# F28x7x_adc_regs register map
Vendor: Texas Instruments
Peripheral module from a debugger description file (folder C2000).
Address unit: 16 bits
Registers are 16-bit, read-write, no defined reset value unless marked. A register's access mark holds for its fields unless they carry their own. Offsets are as the file gives them; lines under a group give offsets from that group; [hi:lo] are bit positions; {n}, {i} and the like mark numbered series; 'fields as' and 'values as' point back to an identical list; <NAME> marks a mode.

## ADC_REGS
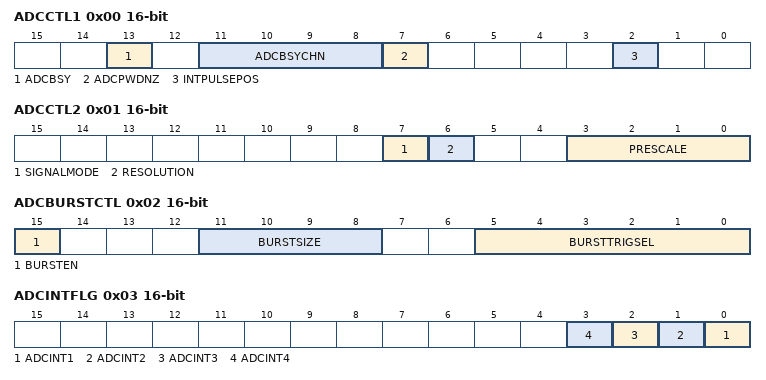
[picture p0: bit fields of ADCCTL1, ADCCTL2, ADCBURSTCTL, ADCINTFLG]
0x00 ADCCTL1 — ADC Control 1 Register
  [13] ADCBSY — ADC Busy
  [11:8] ADCBSYCHN — ADC Busy Channel
  [7] ADCPWDNZ — ADC Power Down
  [2] INTPULSEPOS — ADC Interrupt Pulse Position
0x01 ADCCTL2 — ADC Control 2 Register
  [7] SIGNALMODE — SOC Signaling Mode
  [6] RESOLUTION — SOC Conversion Resolution
  [3:0] PRESCALE — ADC Clock Prescaler
0x02 ADCBURSTCTL — ADC Burst Control Register
  [15] BURSTEN — SOC Burst Mode Enable
  [11:8] BURSTSIZE — SOC Burst Size Select
  [5:0] BURSTTRIGSEL — SOC Burst Trigger Source Select
0x03 ADCINTFLG — ADC Interrupt Flag Register
  [n-1] ADCINT{n} (n=1..4) — ADC Interrupt {n} Flag
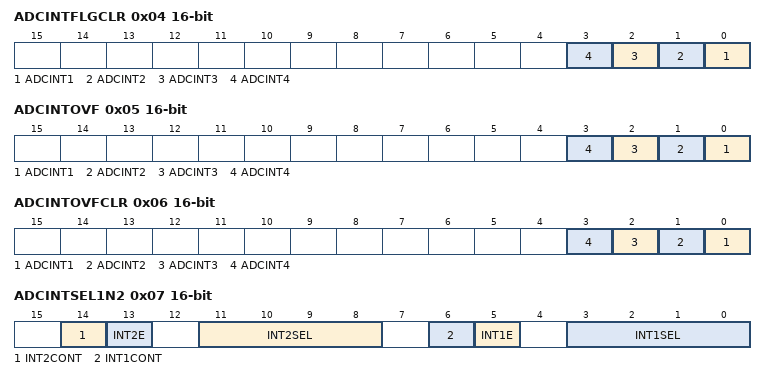
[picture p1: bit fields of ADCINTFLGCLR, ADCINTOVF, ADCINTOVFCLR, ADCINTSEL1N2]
0x04 ADCINTFLGCLR — ADC Interrupt Flag Clear Register
  [n-1] ADCINT{n} (n=1..4) — ADC Interrupt {n} Flag Clear
0x05 ADCINTOVF — ADC Interrupt Overflow Register
  [n-1] ADCINT{n} (n=1..4) — ADC Interrupt {n} Overflow Flags
0x06 ADCINTOVFCLR — ADC Interrupt Overflow Clear Register
  [n-1] ADCINT{n} (n=1..4) — ADC Interrupt {n} Overflow Clear Bits
0x07 ADCINTSEL1N2 — ADC Interrupt 1 and 2 Selection Register
  [14] INT2CONT — ADCINT2 Continuous Mode Enable
  [13] INT2E — ADCINT2 Interrupt Enable
  [11:8] INT2SEL — ADCINT2 EOC Source Select
  [6] INT1CONT — ADCINT1 Continuous Mode Enable
  [5] INT1E — ADCINT1 Interrupt Enable
  [3:0] INT1SEL — ADCINT1 EOC Source Select
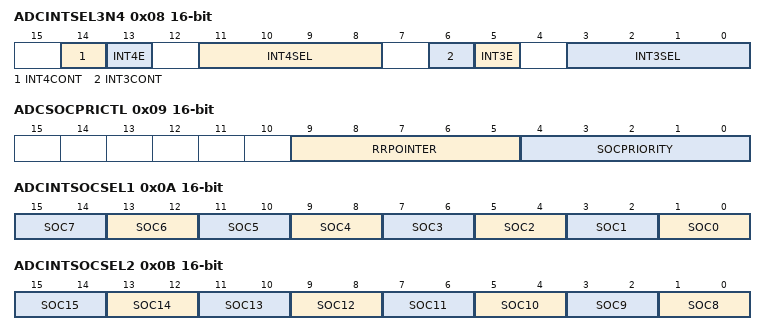
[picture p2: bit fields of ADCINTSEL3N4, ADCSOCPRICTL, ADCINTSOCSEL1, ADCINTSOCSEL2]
0x08 ADCINTSEL3N4 — ADC Interrupt 3 and 4 Selection Register
  [14] INT4CONT — ADCINT4 Continuous Mode Enable
  [13] INT4E — ADCINT4 Interrupt Enable
  [11:8] INT4SEL — ADCINT4 EOC Source Select
  [6] INT3CONT — ADCINT3 Continuous Mode Enable
  [5] INT3E — ADCINT3 Interrupt Enable
  [3:0] INT3SEL — ADCINT3 EOC Source Select
0x09 ADCSOCPRICTL — ADC SOC Priority Control Register
  [9:5] RRPOINTER — Round Robin Pointer
  [4:0] SOCPRIORITY
0x0A ADCINTSOCSEL1 — ADC Interrupt SOC Selection 1 Register
  [2n+1:2n] SOC{n} (n=0..7) — SOC{n} ADC Interrupt Trigger Select
0x0B ADCINTSOCSEL2 — ADC Interrupt SOC Selection 2 Register
  [2n-15:2n-16] SOC{n} (n=8..15) — SOC{n} ADC Interrupt Trigger Select
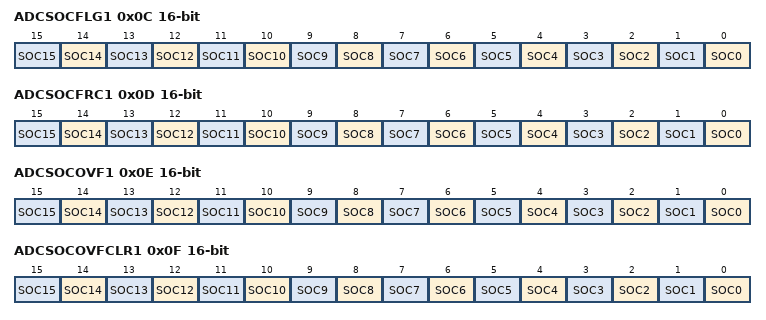
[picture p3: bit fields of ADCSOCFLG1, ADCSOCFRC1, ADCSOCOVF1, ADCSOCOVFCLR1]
0x0C ADCSOCFLG1 — ADC SOC Flag 1 Register
  [n] SOC{n} (n=0..15) — SOC{n} Start of Conversion Flag
0x0D ADCSOCFRC1 — ADC SOC Force 1 Register
  [n] SOC{n} (n=0..15) — SOC{n} Force Start of Conversion Bit
0x0E ADCSOCOVF1 — ADC SOC Overflow 1 Register
  [n] SOC{n} (n=0..15) — SOC{n} Start of Conversion Overflow Flag
0x0F ADCSOCOVFCLR1 — ADC SOC Overflow Clear 1 Register
  [n] SOC{n} (n=0..15) — SOC{n} Clear Start of Conversion Overflow Bit
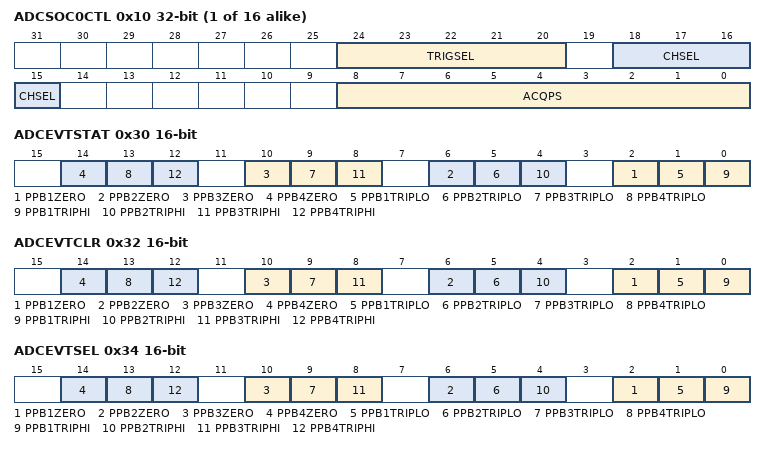
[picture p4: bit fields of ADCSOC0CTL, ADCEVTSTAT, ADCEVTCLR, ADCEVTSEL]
{0x10+2i} ADCSOC{i}CTL 32-bit (i=0..15) — ADC SOC{i} Control Register
  [24:20] TRIGSEL — SOC Trigger Source Select
  [18:15] CHSEL — SOC Channel Select
  [8:0] ACQPS — SOC Acquisition Prescale
0x30 ADCEVTSTAT — ADC Event Status Register
  [4n-2] PPB{n}ZERO (n=1..4) — Post Processing Block {n} Zero Crossing Flag
  [4n-3] PPB{n}TRIPLO (n=1..4) — Post Processing Block {n} Trip Low Flag
  [4n-4] PPB{n}TRIPHI (n=1..4) — Post Processing Block {n} Trip High Flag
0x32 ADCEVTCLR — ADC Event Clear Register
  [4n-2] PPB{n}ZERO (n=1..4) — Post Processing Block {n} Zero Crossing Clear
  [4n-3] PPB{n}TRIPLO (n=1..4) — Post Processing Block {n} Trip Low Clear
  [4n-4] PPB{n}TRIPHI (n=1..4) — Post Processing Block {n} Trip High Clear
0x34 ADCEVTSEL — ADC Event Selection Register
  [4n-2] PPB{n}ZERO (n=1..4) — Post Processing Block {n} Zero Crossing Event Enable
  [4n-3] PPB{n}TRIPLO (n=1..4) — Post Processing Block {n} Trip Low Event Enable
  [4n-4] PPB{n}TRIPHI (n=1..4) — Post Processing Block {n} Trip High Event Enable
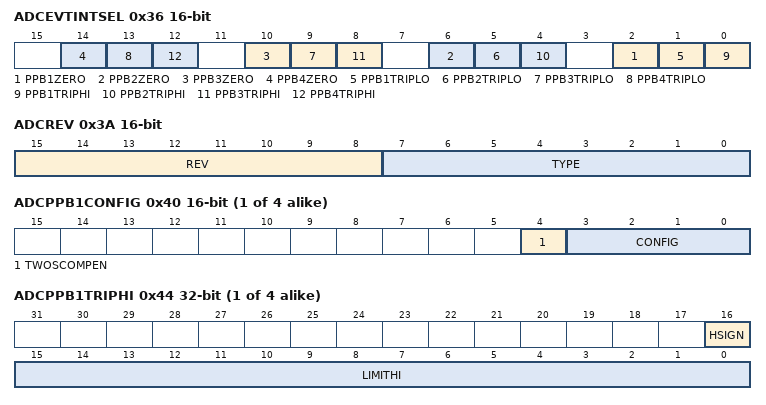
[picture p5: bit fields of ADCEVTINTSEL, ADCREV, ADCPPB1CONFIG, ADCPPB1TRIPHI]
0x36 ADCEVTINTSEL — ADC Event Interrupt Selection Register
  [4n-2] PPB{n}ZERO (n=1..4) — Post Processing Block {n} Zero Crossing Interrupt Enable
  [4n-3] PPB{n}TRIPLO (n=1..4) — Post Processing Block {n} Trip Low Interrupt Enable
  [4n-4] PPB{n}TRIPHI (n=1..4) — Post Processing Block {n} Trip High Interrupt Enable
0x39 ADCCOUNTER
  [11:0] FREECOUNT — ADC Free Running Counter Value
0x3A ADCREV — ADC Revision Register
  [15:8] REV — ADC Revision
  [7:0] TYPE — ADC Type
0x3B ADCOFFTRIM — ADC Offset Trim Register
  [7:0] OFFTRIM — ADC Offset Trim
{0x38+8i} ADCPPB{i}CONFIG (i=1..4)
  [4] TWOSCOMPEN — ADC Post Processing Block Two's Complement Enable
  [3:0] CONFIG — ADC Post Processing Block Configuration
{0x39+8i} ADCPPB{i}STAMP (i=1..4) — ADC PPB{i} Sample Delay Time Stamp Register
  [11:0] DLYSTAMP — ADC Post Processing Block Delay Time Stamp
{0x3A+8i} ADCPPB{i}OFFCAL (i=1..4) — ADC PPB{i} Offset Calibration Register
  [9:0] OFFCAL — ADC Post Processing Block Offset Correction
{0x3B+8i} ADCPPB{i}OFFREF (i=1..4) — ADC PPB{i} Offset Reference Register
  [15:0] OFFREF — ADC Post Processing Block Offset Reference
{0x3C+8i} ADCPPB{i}TRIPHI 32-bit (i=1..4) — ADC PPB{i} Trip High Register
  [16] HSIGN — High Limit Sign Bit
  [15:0] LIMITHI — ADC Post Processing Block Trip High Limit
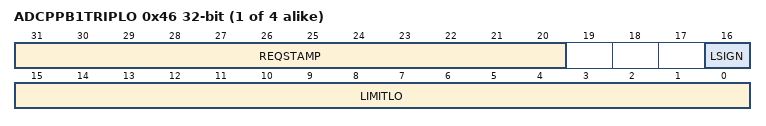
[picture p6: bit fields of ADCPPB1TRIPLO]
{0x3E+8i} ADCPPB{i}TRIPLO 32-bit (i=1..4) — ADC PPB{i} Trip Low/Trigger Time Stamp Register
  [31:20] REQSTAMP — ADC Post Processing Block Request Time Stamp
  [16] LSIGN — Low Limit Sign Bit
  [15:0] LIMITLO — ADC Post Processing Block Trip Low Limit
